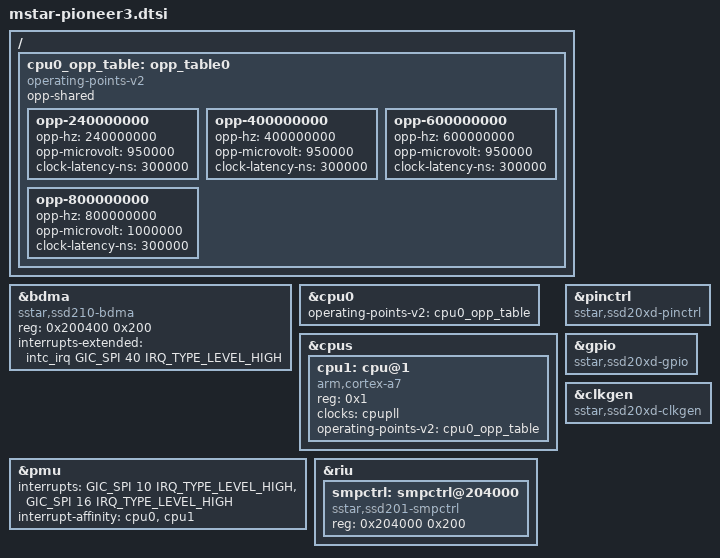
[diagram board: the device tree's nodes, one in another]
// SPDX-License-Identifier: GPL-2.0-or-later
/*
 * Copyright (c) 2020 thingy.jp.
 * Author: Daniel Palmer <daniel@thingy.jp>
 */

#include "mstar-v7.dtsi"

/ {
	cpu0_opp_table: opp_table0 {
		compatible = "operating-points-v2";
		opp-shared;

		opp-240000000 {
			opp-hz = /bits/ 64 <240000000>;
			opp-microvolt = <950000>;
			clock-latency-ns = <300000>;
		};

		opp-400000000 {
			opp-hz = /bits/ 64 <400000000>;
			opp-microvolt = <950000>;
			clock-latency-ns = <300000>;
		};
		opp-600000000 {
			opp-hz = /bits/ 64 <600000000>;
			opp-microvolt = <950000>;
			clock-latency-ns = <300000>;
		};

		opp-800000000 {
			opp-hz = /bits/ 64 <800000000>;
			opp-microvolt = <1000000>;
			clock-latency-ns = <300000>;
		};
	};
};

&bdma {
	compatible = "sstar,ssd210-bdma";
	reg = <0x200400 0x200>;
	interrupts-extended = <&intc_irq GIC_SPI 40 IRQ_TYPE_LEVEL_HIGH>;
};

&cpu0 {
	operating-points-v2 = <&cpu0_opp_table>;
};

&cpus {
	cpu1: cpu@1 {
		device_type = "cpu";
		compatible = "arm,cortex-a7";
		reg = <0x1>;
		clocks = <&cpupll>;
		clock-names = "cpuclk";
		operating-points-v2 = <&cpu0_opp_table>;
	};
};

&pinctrl {
	compatible = "sstar,ssd20xd-pinctrl";
};

&gpio {
	compatible = "sstar,ssd20xd-gpio";
	/delete-property/ gpio-ranges;
	status = "okay";
};

&pmu {
		interrupts = <GIC_SPI 10 IRQ_TYPE_LEVEL_HIGH>,
			     <GIC_SPI 16 IRQ_TYPE_LEVEL_HIGH>;
		interrupt-affinity = <&cpu0>, <&cpu1>;
};

&riu {
	smpctrl: smpctrl@204000 {
		compatible = "sstar,ssd201-smpctrl", "mstar,smpctrl";
		reg = <0x204000 0x200>;
	};
};

&clkgen {
	compatible = "sstar,ssd20xd-clkgen";
};
